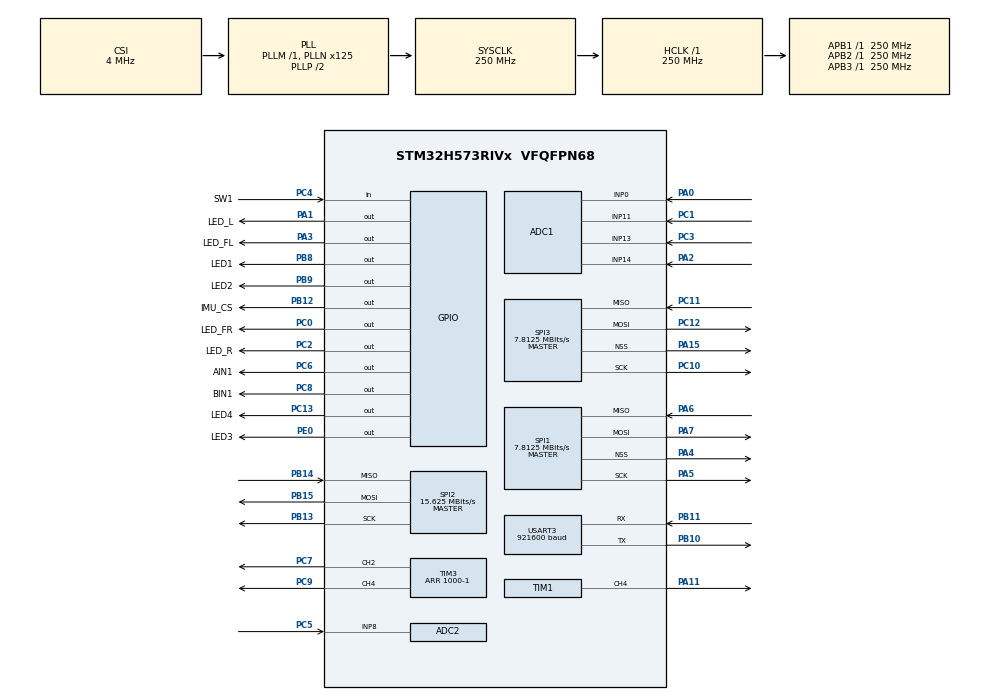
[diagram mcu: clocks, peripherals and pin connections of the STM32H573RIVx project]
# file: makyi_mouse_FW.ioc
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ADC1.Channel-0\#ChannelRegularConversion=ADC_CHANNEL_0
ADC1.ClockPrescaler=ADC_CLOCK_ASYNC_DIV10
ADC1.ContinuousConvMode=DISABLE
ADC1.DiscontinuousConvMode=DISABLE
ADC1.MonitoredBy-0\#ChannelRegularConversion=__NULL
ADC1.NbrOfConversion=1
ADC1.NbrOfConversionFlag=1
ADC1.OffsetNumber-0\#ChannelRegularConversion=ADC_OFFSET_NONE
ADC1.Rank-0\#ChannelRegularConversion=1
ADC1.SamplingTime-0\#ChannelRegularConversion=ADC_SAMPLETIME_12CYCLES_5
ADC1.master=1
ADC2.Channel-0\#ChannelRegularConversion=ADC_CHANNEL_8
ADC2.ClockPrescaler=ADC_CLOCK_ASYNC_DIV10
ADC2.ContinuousConvMode=ENABLE
ADC2.DMAContinuousRequests=ENABLE
ADC2.MonitoredBy-0\#ChannelRegularConversion=__NULL
ADC2.NbrOfConversionFlag=1
ADC2.OffsetNumber-0\#ChannelRegularConversion=ADC_OFFSET_NONE
ADC2.Rank-0\#ChannelRegularConversion=1
ADC2.SamplingTime-0\#ChannelRegularConversion=ADC_SAMPLETIME_24CYCLES_5
BOOTPATH.BootPathName=LEGACY
BOOTPATH.UserSelectedBootPath=LEGACY
CORTEX_M33_NS.userName=CORTEX_M33
GPDMA1.CIRCULARMODE_GPDMACH2=ENABLE
GPDMA1.DESTBURSTLENGTH_GPDMACH2=1
GPDMA1.DESTDATAWIDTH_GPDMACH2=DMA_DEST_DATAWIDTH_WORD
GPDMA1.DIRECTION_GPDMACH0=DMA_MEMORY_TO_PERIPH
GPDMA1.IPHANDLE_GPDMACH0-SIMPLEREQUEST_GPDMACH0=__NULL
GPDMA1.IPHANDLE_GPDMACH1-SIMPLEREQUEST_GPDMACH1=__NULL
GPDMA1.IPHANDLE_GPDMACH2-SIMPLEREQUEST_GPDMACH2=__NULL
GPDMA1.LINKALLOCATEDPORT_CIRCULAR_GPDMACH2=DMA_LINK_ALLOCATED_PORT0
GPDMA1.REQUEST_GPDMACH0=GPDMA1_REQUEST_USART3_TX
GPDMA1.REQUEST_GPDMACH1=GPDMA1_REQUEST_USART3_RX
GPDMA1.REQUEST_GPDMACH2=GPDMA1_REQUEST_ADC2
GPDMA1.SRCBURSTLENGTH_GPDMACH2=1
GPDMA1.SRCDATAWIDTH_GPDMACH2=DMA_SRC_DATAWIDTH_WORD
GPDMA1.SRCINC_GPDMACH0=DMA_SINC_INCREMENTED
GPDMA1.SRCINC_GPDMACH1=DMA_SINC_INCREMENTED
GPDMA1.TRANSFERALLOCATEDPORTSRC_GPDMACH0=DMA_SRC_ALLOCATED_PORT1
GPDMA1.TRANSFERALLOCATEDPORTSRC_GPDMACH1=DMA_SRC_ALLOCATED_PORT1
GPDMA1.TRANSFERALLOCATEDPORTSRC_GPDMACH2=DMA_SRC_ALLOCATED_PORT1
Mcu.Family=STM32H5
Mcu.Name=STM32H573RIVx
Mcu.Package=VFQFPN68
NVIC.ADC2_IRQn=true\:0\:0\:false\:false\:true\:true\:true\:true
NVIC.GPDMA1_Channel0_IRQn=true\:0\:0\:false\:false\:true\:false\:true\:true
NVIC.GPDMA1_Channel1_IRQn=true\:0\:0\:false\:false\:true\:false\:true\:true
NVIC.GPDMA1_Channel2_IRQn=true\:0\:0\:false\:false\:true\:true\:true\:true
NVIC.PriorityGroup=NVIC_PRIORITYGROUP_4
NVIC.TIM16_IRQn=true\:0\:0\:false\:false\:true\:true\:true\:true
NVIC.TIM17_IRQn=true\:0\:0\:false\:false\:true\:true\:true\:true
NVIC.USART3_IRQn=true\:0\:0\:false\:false\:true\:true\:true\:true
PA0.Signal=ADCx_INP0
PA1.GPIO_Label=LED_L
PA1.Signal=GPIO_Output
PA11.Signal=S_TIM1_CH4
PA13(JTMS/SWDIO).Mode=Serial_Wire
PA13(JTMS/SWDIO).Signal=DEBUG_JTMS-SWDIO
PA14(JTCK/SWCLK).Mode=Serial_Wire
PA14(JTCK/SWCLK).Signal=DEBUG_JTCK-SWCLK
PA15(JTDI).Mode=NSS_Signal_Hard_Output
PA15(JTDI).Signal=SPI3_NSS
PA2.Signal=ADCx_INP14
PA3.GPIO_Label=LED_FL
PA3.Signal=GPIO_Output
PA4.Mode=NSS_Signal_Hard_Output
PA4.Signal=SPI1_NSS
PA5.Mode=Full_Duplex_Master
PA5.Signal=SPI1_SCK
PA6.Mode=Full_Duplex_Master
PA6.Signal=SPI1_MISO
PA7.Mode=Full_Duplex_Master
PA7.Signal=SPI1_MOSI
PB10.Mode=Asynchronous
PB10.Signal=USART3_TX
PB11.Mode=Asynchronous
PB11.Signal=USART3_RX
PB12.GPIO_Label=IMU_CS
PB12.Signal=GPIO_Output
PB13.Mode=Full_Duplex_Master
PB13.Signal=SPI2_SCK
PB14.Mode=Full_Duplex_Master
PB14.Signal=SPI2_MISO
PB15.Mode=Full_Duplex_Master
PB15.Signal=SPI2_MOSI
PB8.GPIO_Label=LED1
PB8.Signal=GPIO_Output
PB9.GPIO_Label=LED2
PB9.Signal=GPIO_Output
PC0.GPIO_Label=LED_FR
PC0.Signal=GPIO_Output
PC1.Signal=ADCx_INP11
PC10.Mode=Full_Duplex_Master
PC10.Signal=SPI3_SCK
PC11.Mode=Full_Duplex_Master
PC11.Signal=SPI3_MISO
PC12.Mode=Full_Duplex_Master
PC12.Signal=SPI3_MOSI
PC13.GPIO_Label=LED4
PC13.Signal=GPIO_Output
PC2.GPIO_Label=LED_R
PC2.Signal=GPIO_Output
PC3.Signal=ADCx_INP13
PC4.GPIO_Label=SW1
PC4.GPIO_PuPd=GPIO_PULLUP
PC4.Signal=GPIO_Input
PC5.Signal=ADCx_INP8
PC6.GPIO_Label=AIN1
PC6.Signal=GPIO_Output
PC7.Signal=S_TIM3_CH2
PC8.GPIO_Label=BIN1
PC8.Signal=GPIO_Output
PC9.Signal=S_TIM3_CH4
PE0.GPIO_Label=LED3
PE0.Signal=GPIO_Output
ProjectManager.HeapSize=0x200
ProjectManager.StackSize=0x400
ProjectManager.TargetToolchain=STM32CubeIDE
RCC.ADCCLockSelection=RCC_ADCDACCLKSOURCE_HSI
RCC.ADCFreq_Value=32000000
RCC.AHBFreq_Value=250000000
RCC.APB1Freq_Value=250000000
RCC.APB1TimFreq_Value=250000000
RCC.APB2Freq_Value=250000000
RCC.APB2TimFreq_Value=250000000
RCC.APB3Freq_Value=250000000
RCC.CSI_VALUE=4000000
RCC.CortexFreq_Value=250000000
RCC.EPOD_VALUE=4000000
RCC.HCLKFreq_Value=250000000
RCC.HSE_VALUE=25000000
RCC.HSI48_VALUE=48000000
RCC.HSI_VALUE=64000000
RCC.LSE_VALUE=32768
RCC.LSIRC_VALUE=32000
RCC.PLL2FRACN=0
RCC.PLL3FRACN=0
RCC.PLLFRACN=0
RCC.PLLN=125
RCC.SYSCLKFreq_VALUE=250000000
RCC.SYSCLKSource=RCC_SYSCLKSOURCE_PLLCLK
RCC.USBFreq_Value=48000000
RCC.VCOOutputFreq_Value=500000000
SH.ADCx_INP0.0=ADC1_INP0,IN0-Single-Ended
SH.ADCx_INP11.0=ADC1_INP11,IN11-Single-Ended
SH.ADCx_INP13.0=ADC1_INP13,IN13-Single-Ended
SH.ADCx_INP14.0=ADC1_INP14,IN14-Single-Ended
SH.ADCx_INP8.0=ADC2_INP8,IN8-Single-Ended
SH.S_TIM1_CH4.0=TIM1_CH4,PWM Generation4 CH4
SH.S_TIM3_CH2.0=TIM3_CH2,PWM Generation2 CH2
SH.S_TIM3_CH4.0=TIM3_CH4,PWM Generation4 CH4
SPI1.BaudRatePrescaler=SPI_BAUDRATEPRESCALER_32
SPI1.CalculateBaudRate=7.8125 MBits/s
SPI1.DataSize=SPI_DATASIZE_16BIT
SPI1.Direction=SPI_DIRECTION_2LINES
SPI1.Mode=SPI_MODE_MASTER
SPI1.VirtualNSS=VM_NSSHARD
SPI1.VirtualType=VM_MASTER
SPI2.BaudRatePrescaler=SPI_BAUDRATEPRESCALER_16
SPI2.CLKPhase=SPI_PHASE_2EDGE
SPI2.CLKPolarity=SPI_POLARITY_HIGH
SPI2.CalculateBaudRate=15.625 MBits/s
SPI2.DataSize=SPI_DATASIZE_8BIT
SPI2.Direction=SPI_DIRECTION_2LINES
SPI2.Mode=SPI_MODE_MASTER
SPI2.VirtualType=VM_MASTER
SPI3.BaudRatePrescaler=SPI_BAUDRATEPRESCALER_32
SPI3.CalculateBaudRate=7.8125 MBits/s
SPI3.DataSize=SPI_DATASIZE_16BIT
SPI3.Direction=SPI_DIRECTION_2LINES
SPI3.Mode=SPI_MODE_MASTER
SPI3.VirtualNSS=VM_NSSHARD
SPI3.VirtualType=VM_MASTER
TIM1.Channel-PWM\ Generation4\ CH4=TIM_CHANNEL_4
TIM1.Prescaler=250
TIM16.PeriodNoDither=1000-1
TIM16.Prescaler=250-1
TIM17.PeriodNoDither=125-1
TIM17.Prescaler=250-1
TIM3.Channel-PWM\ Generation2\ CH2=TIM_CHANNEL_2
TIM3.Channel-PWM\ Generation4\ CH4=TIM_CHANNEL_4
TIM3.PeriodNoDither=1000-1
USART3.BaudRate=921600
USART3.VirtualMode=VM_ASYNC
VP_BOOTPATH_VS_BOOTPATH.Mode=BP_Activate
VP_CORTEX_M33_NS_VS_Hclk.Mode=Hclk_Mode
VP_FLASH_SIG_Activate_FlashIP.Mode=Activate_FlashIP
VP_GPDMA1_VS_GPDMACH0.Mode=SIMPLEREQUEST_GPDMACH0
VP_GPDMA1_VS_GPDMACH1.Mode=SIMPLEREQUEST_GPDMACH1
VP_GPDMA1_VS_GPDMACH2.Mode=SIMPLEREQUEST_GPDMACH2
VP_ICACHE_VS_ENABLE_ICACHE_MEMORY.Mode=Memoryregions
VP_MEMORYMAP_VS_MEMORYMAP.Mode=CurAppReg
VP_PWR_VS_DBSignals.Mode=DisableDeadBatterySignals
VP_PWR_VS_LPOM.Mode=PowerOptimisation
VP_PWR_VS_SECSignals.Mode=Security/Privilege
VP_TIM16_VS_ClockSourceINT.Mode=Enable_Timer
VP_TIM17_VS_ClockSourceINT.Mode=Enable_Timer
board=custom

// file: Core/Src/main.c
/* USER CODE BEGIN Header */
/**
  ******************************************************************************
  * @file           : main.c
  * @brief          : Main program body
  ******************************************************************************
  * @attention
  *
  * Copyright (c) 2024 STMicroelectronics.
  * All rights reserved.
  *
  * This software is licensed under terms that can be found in the LICENSE file
  * in the root directory of this software component.
  * If no LICENSE file comes with this software, it is provided AS-IS.
  *
  ******************************************************************************
  */
/* USER CODE END Header */
#include "main.h"
#include "adc.h"
#include "flash.h"
#include "gpdma.h"
#include "icache.h"
#include "memorymap.h"
#include "spi.h"
#include "tim.h"
#include "usart.h"
#include "gpio.h"

/* USER CODE BEGIN Includes */
#include "c_wrapper.h"

/* USER CODE END Includes */

void SystemClock_Config(void);

/* USER CODE BEGIN 0 */
int _write(int file, char *ptr, int len){
	HAL_UART_Transmit_DMA(&huart3, (uint8_t *)ptr, len);
//	HAL_UART_Transmit(&huart3, (uint8_t *)ptr, len,1000);
	return len;
}

/* USER CODE END 0 */

int main(void)
{

  /* MCU Configuration--------------------------------------------------------*/

  /* Reset of all peripherals, Initializes the Flash interface and the Systick. */
	HAL_Init();

  /* Configure the system clock */
  SystemClock_Config();

  /* Initialize all configured peripherals */
  MX_GPIO_Init();
  MX_GPDMA1_Init();
  MX_SPI1_Init();
  MX_ICACHE_Init();
  MX_SPI3_Init();
  MX_USART3_UART_Init();
  MX_SPI2_Init();
  MX_TIM1_Init();
  MX_TIM3_Init();
  MX_ADC2_Init();
  MX_TIM16_Init();
  MX_ADC1_Init();
  MX_TIM17_Init();
  MX_FLASH_Init();
  /* USER CODE BEGIN 2 */
  Init();

  /* USER CODE END 2 */

  /* Infinite loop */
  while (1)
  {

    /* USER CODE BEGIN 3 */
	Loop();
  }
  /* USER CODE END 3 */
}

void SystemClock_Config(void)
{
  RCC_OscInitTypeDef RCC_OscInitStruct = {0};
  RCC_ClkInitTypeDef RCC_ClkInitStruct = {0};

  /** Configure the main internal regulator output voltage
  */
  __HAL_PWR_VOLTAGESCALING_CONFIG(PWR_REGULATOR_VOLTAGE_SCALE0);

  while(!__HAL_PWR_GET_FLAG(PWR_FLAG_VOSRDY)) {}

  /** Initializes the RCC Oscillators according to the specified parameters
  * in the RCC_OscInitTypeDef structure.
  */
  RCC_OscInitStruct.OscillatorType = RCC_OSCILLATORTYPE_HSI|RCC_OSCILLATORTYPE_CSI;
  RCC_OscInitStruct.HSIState = RCC_HSI_ON;
  RCC_OscInitStruct.HSIDiv = RCC_HSI_DIV2;
  RCC_OscInitStruct.HSICalibrationValue = RCC_HSICALIBRATION_DEFAULT;
  RCC_OscInitStruct.CSIState = RCC_CSI_ON;
  RCC_OscInitStruct.CSICalibrationValue = RCC_CSICALIBRATION_DEFAULT;
  RCC_OscInitStruct.PLL.PLLState = RCC_PLL_ON;
  RCC_OscInitStruct.PLL.PLLSource = RCC_PLL1_SOURCE_CSI;
  RCC_OscInitStruct.PLL.PLLM = 1;
  RCC_OscInitStruct.PLL.PLLN = 125;
  RCC_OscInitStruct.PLL.PLLP = 2;
  RCC_OscInitStruct.PLL.PLLQ = 2;
  RCC_OscInitStruct.PLL.PLLR = 2;
  RCC_OscInitStruct.PLL.PLLRGE = RCC_PLL1_VCIRANGE_2;
  RCC_OscInitStruct.PLL.PLLVCOSEL = RCC_PLL1_VCORANGE_WIDE;
  RCC_OscInitStruct.PLL.PLLFRACN = 0;
  if (HAL_RCC_OscConfig(&RCC_OscInitStruct) != HAL_OK)
  {
    Error_Handler();
  }

  /** Initializes the CPU, AHB and APB buses clocks
  */
  RCC_ClkInitStruct.ClockType = RCC_CLOCKTYPE_HCLK|RCC_CLOCKTYPE_SYSCLK
                              |RCC_CLOCKTYPE_PCLK1|RCC_CLOCKTYPE_PCLK2
                              |RCC_CLOCKTYPE_PCLK3;
  RCC_ClkInitStruct.SYSCLKSource = RCC_SYSCLKSOURCE_PLLCLK;
  RCC_ClkInitStruct.AHBCLKDivider = RCC_SYSCLK_DIV1;
  RCC_ClkInitStruct.APB1CLKDivider = RCC_HCLK_DIV1;
  RCC_ClkInitStruct.APB2CLKDivider = RCC_HCLK_DIV1;
  RCC_ClkInitStruct.APB3CLKDivider = RCC_HCLK_DIV1;

  if (HAL_RCC_ClockConfig(&RCC_ClkInitStruct, FLASH_LATENCY_5) != HAL_OK)
  {
    Error_Handler();
  }
}

void Error_Handler(void)
{
  __disable_irq();
  while (1)
  {
  }
}
